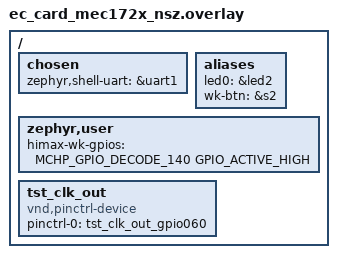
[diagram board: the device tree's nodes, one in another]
/*
 * Copyright (c) 2023 Microchip Technology Inc.
 *
 * SPDX-License-Identifier: Apache-2.0
 */

/ {
    chosen {
        zephyr,shell-uart = &uart1;
    };

    aliases {
        led0 = &led2;
        wk-btn = &s2;
    };

    zephyr,user {
        himax-wk-gpios = <MCHP_GPIO_DECODE_140 GPIO_ACTIVE_HIGH>;
    };

    tst_clk_out: tst_clk_out {
        compatible = "vnd,pinctrl-device";
        pinctrl-0 = <&tst_clk_out_gpio060>;
        pinctrl-names = "default";
        status = "okay";
    };
};
